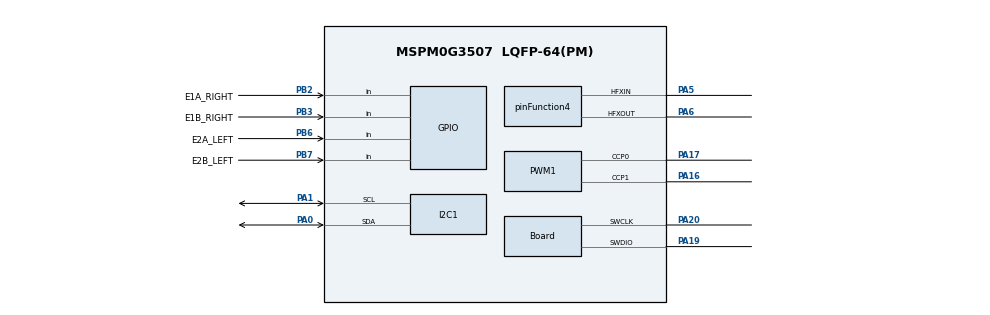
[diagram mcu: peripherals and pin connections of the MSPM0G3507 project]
//@cliArgs --device "MSPM0G350X" --package "LQFP-64(PM)" --part "Default"
//@v2CliArgs --device "MSPM0G3507" --package "LQFP-64(PM)"
// @cliArgs --board /ti/boards/LP_MSPM0G3507 --rtos nortos

/**
 * Import the modules used in this configuration.
 */
const SYSCTL = scripting.addModule("/ti/driverlib/SYSCTL");
const GPIO   = scripting.addModule("/ti/driverlib/GPIO", {}, false);
const GPIO1  = GPIO.addInstance();
const GPIO2  = GPIO.addInstance();
const PWM    = scripting.addModule("/ti/driverlib/PWM", {}, false);
const PWM1   = PWM.addInstance();
const I2C    = scripting.addModule("/ti/driverlib/I2C", {}, false);
const I2C1   = I2C.addInstance();

/**
 * Write custom configuration values to the imported modules.
 */
const divider9       = system.clockTree["UDIV"];
divider9.divideValue = 2;

const gate7  = system.clockTree["MFCLKGATE"];
gate7.enable = true;

const multiplier2         = system.clockTree["PLL_QDIV"];
multiplier2.multiplyValue = 4;

const mux4       = system.clockTree["EXHFMUX"];
mux4.inputSelect = "EXHFMUX_XTAL";

const mux8       = system.clockTree["HSCLKMUX"];
mux8.inputSelect = "HSCLKMUX_SYSPLL0";

const mux12       = system.clockTree["SYSPLLMUX"];
mux12.inputSelect = "zSYSPLLMUX_HFCLK";

const pinFunction4        = system.clockTree["HFXT"];
pinFunction4.inputFreq    = 40;
pinFunction4.enable       = true;
pinFunction4.HFXTStartup  = 10;
pinFunction4.HFCLKMonitor = true;
pinFunction4.peripheral.$assign           = "SYSCTL";
pinFunction4.peripheral.hfxInPin.$assign  = "PA5";
pinFunction4.peripheral.hfxOutPin.$assign = "PA6";

SYSCTL.forceDefaultClkConfig = true;
SYSCTL.clockTreeEn  = true;

GPIO1.$name                          = "TB6612";
GPIO1.associatedPins.create(4);
GPIO1.associatedPins[0].$name        = "AIN1";
GPIO1.associatedPins[0].assignedPort = "PORTA";
GPIO1.associatedPins[0].assignedPin  = "14";
GPIO1.associatedPins[0].initialValue = "CLEARED";
GPIO1.associatedPins[1].$name        = "AIN2";
GPIO1.associatedPins[1].assignedPort = "PORTA";
GPIO1.associatedPins[1].assignedPin  = "15";
GPIO1.associatedPins[1].initialValue = "CLEARED";
GPIO1.associatedPins[2].$name        = "BIN1";
GPIO1.associatedPins[2].assignedPort = "PORTA";
GPIO1.associatedPins[2].assignedPin  = "12";
GPIO1.associatedPins[2].initialValue = "CLEARED";
GPIO1.associatedPins[3].$name        = "BIN2";
GPIO1.associatedPins[3].assignedPort = "PORTA";
GPIO1.associatedPins[3].assignedPin  = "13";
GPIO1.associatedPins[3].initialValue = "CLEARED";

GPIO2.$name                               = "ENCODER";
GPIO2.associatedPins.create(4);
GPIO2.associatedPins[0].$name             = "E1A_RIGHT";
GPIO2.associatedPins[0].direction         = "INPUT";
GPIO2.associatedPins[0].interruptEn       = true;
GPIO2.associatedPins[0].polarity          = "RISE_FALL";
GPIO2.associatedPins[0].internalResistor  = "PULL_UP";
GPIO2.associatedPins[0].pin.$assign       = "PB2";
GPIO2.associatedPins[1].$name             = "E1B_RIGHT";
GPIO2.associatedPins[1].direction         = "INPUT";
GPIO2.associatedPins[1].interruptEn       = true;
GPIO2.associatedPins[1].polarity          = "RISE_FALL";
GPIO2.associatedPins[1].internalResistor  = "PULL_UP";
GPIO2.associatedPins[1].pin.$assign       = "PB3";
GPIO2.associatedPins[2].$name             = "E2A_LEFT";
GPIO2.associatedPins[2].direction         = "INPUT";
GPIO2.associatedPins[2].interruptEn       = true;
GPIO2.associatedPins[2].polarity          = "RISE_FALL";
GPIO2.associatedPins[2].internalResistor  = "PULL_UP";
GPIO2.associatedPins[2].pin.$assign       = "PB6";
GPIO2.associatedPins[3].$name             = "E2B_LEFT";
GPIO2.associatedPins[3].direction         = "INPUT";
GPIO2.associatedPins[3].interruptEn       = true;
GPIO2.associatedPins[3].polarity          = "RISE_FALL";
GPIO2.associatedPins[3].internalResistor  = "PULL_UP";
GPIO2.associatedPins[3].pin.$assign       = "PB7";

PWM1.$name                      = "MOTOR_PWM";
PWM1.clockSource                = "BUSCLK";
PWM1.clockDivider               = 1;
PWM1.clockPrescale              = 1;
PWM1.timerCount                 = 4000;
PWM1.pwmMode                    = "EDGE_ALIGN";
PWM1.ccIndex                    = [0,1];
PWM1.timerStartTimer            = true;
PWM1.peripheral.$assign         = "TIMA1";
PWM1.peripheral.ccp0Pin.$assign = "PA17";
PWM1.peripheral.ccp1Pin.$assign = "PA16";
PWM1.PWM_CHANNEL_0.$name        = "PWMB_LEFT";
PWM1.PWM_CHANNEL_0.dutyCycle    = 0;
PWM1.PWM_CHANNEL_1.$name        = "PWMA_RIGHT";
PWM1.PWM_CHANNEL_1.dutyCycle    = 0;

I2C1.$name                           = "I2C_OLED";
I2C1.basicClockSourceDivider         = 4;
I2C1.basicEnableController           = true;
I2C1.basicControllerStandardBusSpeed = "Fast";
I2C1.basicControllerBusSpeed         = 500000;
I2C1.peripheral.$assign              = "I2C0";
I2C1.peripheral.sdaPin.$assign       = "PA0";
I2C1.peripheral.sclPin.$assign       = "PA1";

const Board                       = scripting.addModule("/ti/driverlib/Board", {}, false);
Board.peripheral.$assign          = "DEBUGSS";
Board.peripheral.swclkPin.$assign = "PA20";
Board.peripheral.swdioPin.$assign = "PA19";
